# STM32F031C4T6 register map
File version: 1.0
Registers are 32-bit, access not given, reset 0x0 unless marked. A register's access mark holds for its fields unless they carry their own. Offsets are from the block's base; [hi:lo] are bit positions; {n}, {i} and the like mark numbered series.

## CRS
Base 0x40006C00
0x00 CR
  [13:8] TRIM, [7] SWSYNC, [6] AUTOTRIMEN, [5] CEN, [31:4] s, [3] ESYNCIE, [2] ERRIE, [1] SYNCWARNIE, [0] SYNCOKIE
0x04 CFGR
  [31] SYNCPOL, [29:28] SYNCSRC, [30:27] s, [26:24] SYNCDIV, [23:16] FELIM, [15:0] RELOAD
0x08 ISR
  [31:16] FECAP, [15] FEDIR, [10] TRIMOVF, [9] SYNCMISS, [8] SYNCERR, [14:4] s, [3] ESYNCF, [2] ERRF, [1] SYNCWARNF, [0] SYNCOKF
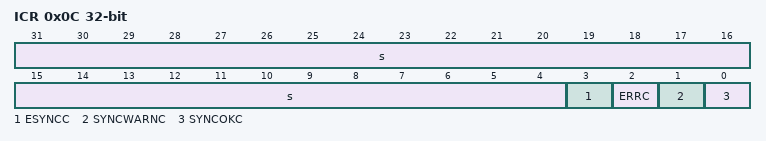
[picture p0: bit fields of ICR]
0x0C ICR
  [31:4] s, [3] ESYNCC, [2] ERRC, [1] SYNCWARNC, [0] SYNCOKC

## PWR
Base 0x40007000
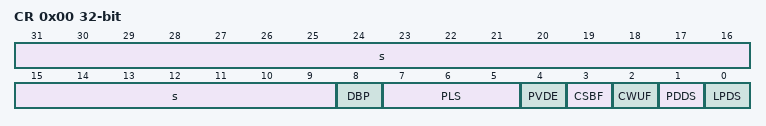
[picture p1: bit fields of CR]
0x00 CR
  [31:9] s, [8] DBP, [7:5] PLS, [4] PVDE, [3] CSBF, [2] CWUF, [1] PDDS, [0] LPDS
0x04 CSR
  [n+7] EWUP{n} (n=1..8), [31:4] s, [3] VREFINTRDY, [2] PVDO, [1] SBF, [0] WUF

## DAC
Base 0x40007400
0x00 CR
  [29] DMAUDRIE2, [28] DMAEN2, [27:24] MAMP2, [23:22] WAVE2, [21:19] TSEL2, [18] TEN2, [17] BOFF2, [16] EN2, [31:14] s, [13] DMAUDRIE1, [12] DMAEN1, [11:8] MAMP1, [7:6] WAVE1, [5:3] TSEL1, [2] TEN1, [1] BOFF1, [0] EN1
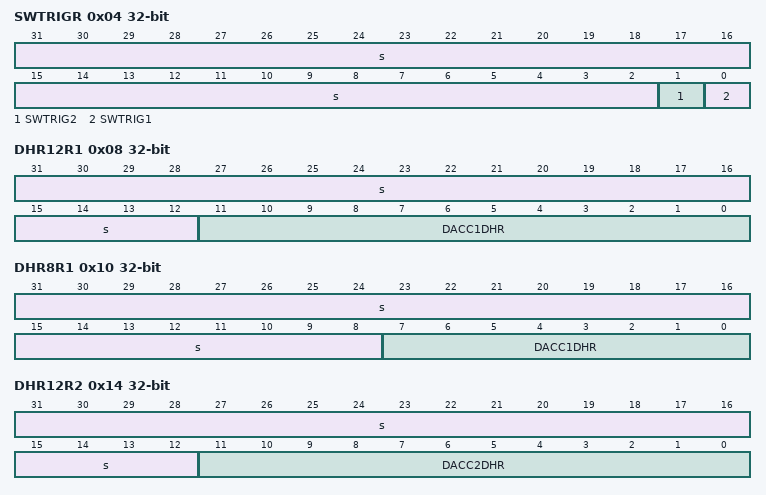
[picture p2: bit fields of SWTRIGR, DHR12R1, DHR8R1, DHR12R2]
0x04 SWTRIGR
  [31:2] s, [1] SWTRIG2, [0] SWTRIG1
0x08 DHR12R1
  [31:12] s, [11:0] DACC1DHR
0x0C DHR12L1
  [15:4] DACC1DHR, [31:0] s
0x10 DHR8R1
  [31:8] s, [7:0] DACC1DHR
0x14 DHR12R2
  [31:12] s, [11:0] DACC2DHR
0x18 DHR12L2
  [15:4] DACC2DHR, [31:0] s
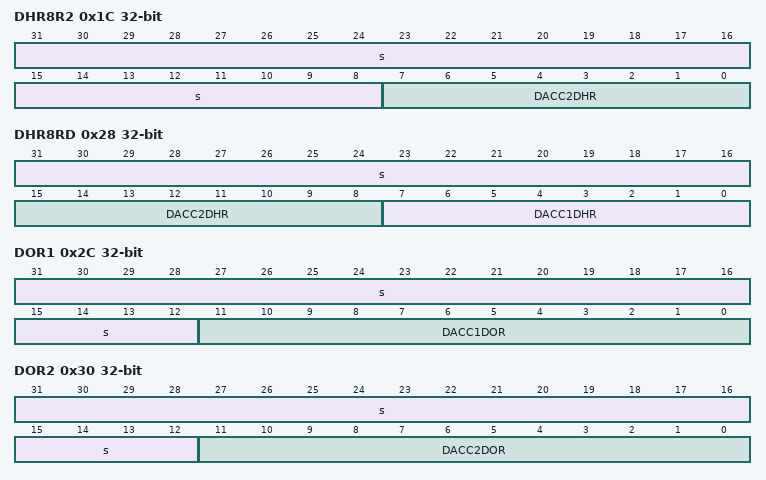
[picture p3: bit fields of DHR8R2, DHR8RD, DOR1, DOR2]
0x1C DHR8R2
  [31:8] s, [7:0] DACC2DHR
0x20 DHR12RD
  [27:16] DACC2DHR, [31:12] s, [11:0] DACC1DHR
0x24 DHR12LD
  [31:20] DACC2DHR, [15:4] DACC1DHR, [19:0] s
0x28 DHR8RD
  [31:16] s, [15:8] DACC2DHR, [7:0] DACC1DHR
0x2C DOR1
  [31:12] s, [11:0] DACC1DOR
0x30 DOR2
  [31:12] s, [11:0] DACC2DOR
0x34 SR
  [29] DMAUDR2, [13] DMAUDR1, [31:0] s

## CEC
Base 0x40007800
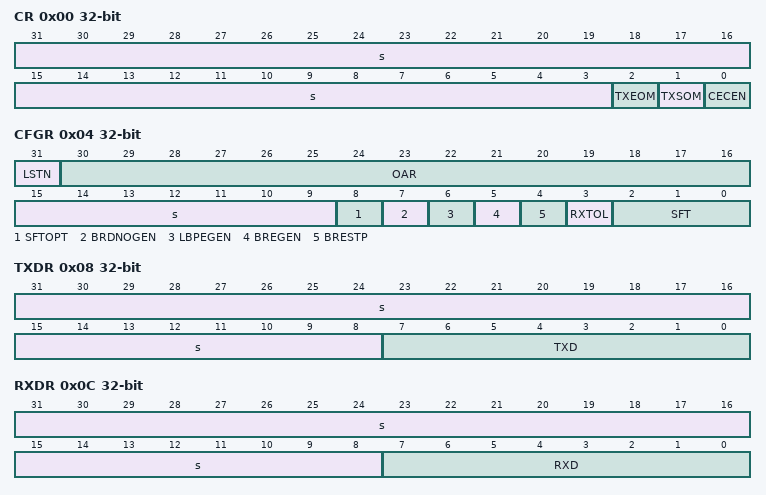
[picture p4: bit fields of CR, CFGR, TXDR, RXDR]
0x00 CR
  [31:3] s, [2] TXEOM, [1] TXSOM, [0] CECEN
0x04 CFGR
  [31] LSTN, [30:16] OAR, [15:9] s, [8] SFTOPT, [7] BRDNOGEN, [6] LBPEGEN, [5] BREGEN, [4] BRESTP, [3] RXTOL, [2:0] SFT
0x08 TXDR
  [31:8] s, [7:0] TXD
0x0C RXDR
  [31:8] s, [7:0] RXD
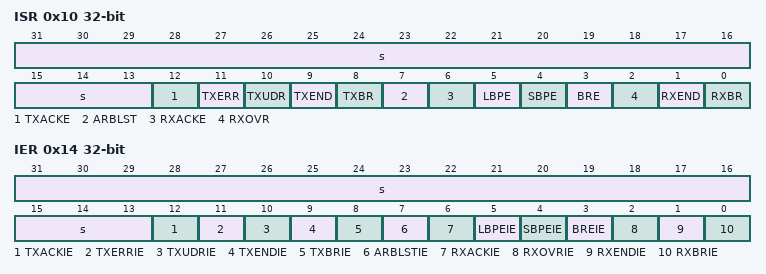
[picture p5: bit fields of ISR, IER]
0x10 ISR
  [31:13] s, [12] TXACKE, [11] TXERR, [10] TXUDR, [9] TXEND, [8] TXBR, [7] ARBLST, [6] RXACKE, [5] LBPE, [4] SBPE, [3] BRE, [2] RXOVR, [1] RXEND, [0] RXBR
0x14 IER
  [31:13] s, [12] TXACKIE, [11] TXERRIE, [10] TXUDRIE, [9] TXENDIE, [8] TXBRIE, [7] ARBLSTIE, [6] RXACKIE, [5] LBPEIE, [4] SBPEIE, [3] BREIE, [2] RXOVRIE, [1] RXENDIE, [0] RXBRIE

## SYSCFGCOMP
Base 0x40010000
0x00 CFGR1
  [30] TIM3_DMA_RMP, [29] TIM2_DMA_RMP, [28] TIM1_DMA_RMP, [27] I2C1_DMA_RMP, [26] USART3_DMA_RMP, [25] USART2_DMA_RMP, [24] SPI2_DMA_RMP, [23] I2C_PA10_FMP, [22] I2C_PA9_FMP, [21] I2C2_FMP, [20] I2C1_FMP, [n+10] I2C_PB{n}_FMP (n=6..9), [14] TIM17_DMA_RMP2, [13] TIM16_DMA_RMP2, [12] TIM17_DMA_RMP, [11] TIM16_DMA_RMP, [10] USART1_RX_DMA_RMP, [9] USART1_TX_DMA_RMP, [8] ADC_DMA_RMP, [7:6] IR_MOD, [4] PA11_PA12_RMP, [31:2] s, [1:0] MEM_MODE
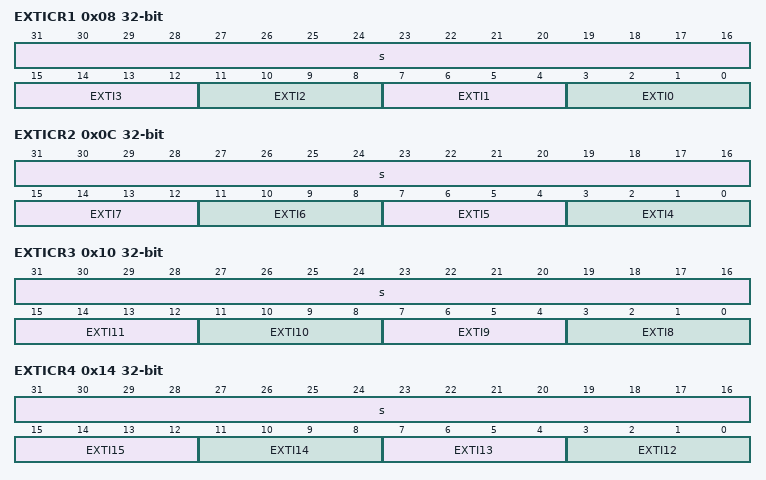
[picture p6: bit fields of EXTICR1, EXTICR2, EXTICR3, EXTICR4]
0x08 EXTICR1
  [31:16] s, [4n+3:4n] EXTI{n} (n=0..3)
0x0C EXTICR2
  [31:16] s, [4n-13:4n-16] EXTI{n} (n=4..7)
0x10 EXTICR3
  [31:16] s, [4n-29:4n-32] EXTI{n} (n=8..11)
0x14 EXTICR4
  [31:16] s, [4n-45:4n-48] EXTI{n} (n=12..15)
0x18 CFGR2
  [8] SRAM_PEF, [31:3] s, [2] PVD_LOCK, [1] SRAM_PARITY_LOCK, [0] LOCUP_LOCK

## EXTI
Base 0x40010400
0x00 IMR
  [31:0] IM
0x04 EMR
  [31:0] EM
0x08 RTSR
  [31] RT31, [n] RT{n} (n=19..23), [30:18] s, [17:0] RT
0x0C FTSR
  [31] FT31, [n] FT{n} (n=19..23), [30:18] s, [17:0] FT
0x10 SWIER
  [31] SWI31, [n] SWI{n} (n=19..23), [30:18] s, [17:0] SWI
0x14 PR
  [31] PIF31, [n] PIF{n} (n=19..23), [30:18] s, [17:0] PIF

## ADC
Base 0x40012400
0x00 ISR
  [7] AWD, [31:5] s, [4] OVR, [3] EOSEQ, [2] EOC, [1] EOSMP, [0] ADRDY
0x04 IER
  [7] AWDIE, [31:5] s, [4] OVRIE, [3] EOSEQIE, [2] EOCIE, [1] EOSMPIE, [0] ADRDYIE
0x08 CR
  [31] ADCAL, [4] ADSTP, [30:3] s, [2] ADSTART, [1] ADDIS, [0] ADEN
0x0C CFGR1
  [30:26] AWDCH, [23] AWDEN, [22] AWDSGL, [16] DISCEN, [15] AUTOFF, [14] WAIT, [13] CONT, [12] OVRMOD, [11:10] EXTEN, [31:9] s, [8:6] EXTSEL, [5] ALIGN, [4:3] RES, [2] SCANDIR, [1] DMACFG, [0] DMAEN
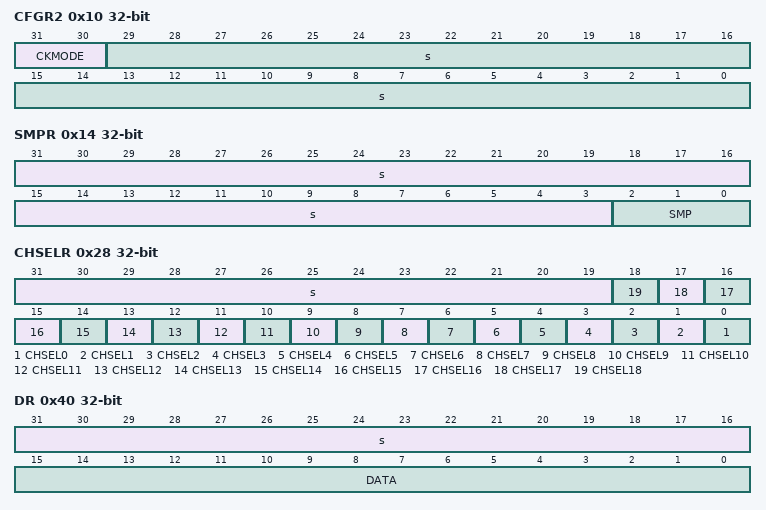
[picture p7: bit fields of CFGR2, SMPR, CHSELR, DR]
0x10 CFGR2
  [31:30] CKMODE, [29:0] s
0x14 SMPR
  [31:3] s, [2:0] SMP
0x20 TR
  [27:16] HT, [31:12] s, [11:0] LT
0x28 CHSELR
  [31:19] s, [n] CHSEL{n} (n=0..18)
0x40 DR
  [31:16] s, [15:0] DATA
0x308 CCR
  [24] VBATEN, [23] TSEN, [22] VREFEN, [31:0] s
